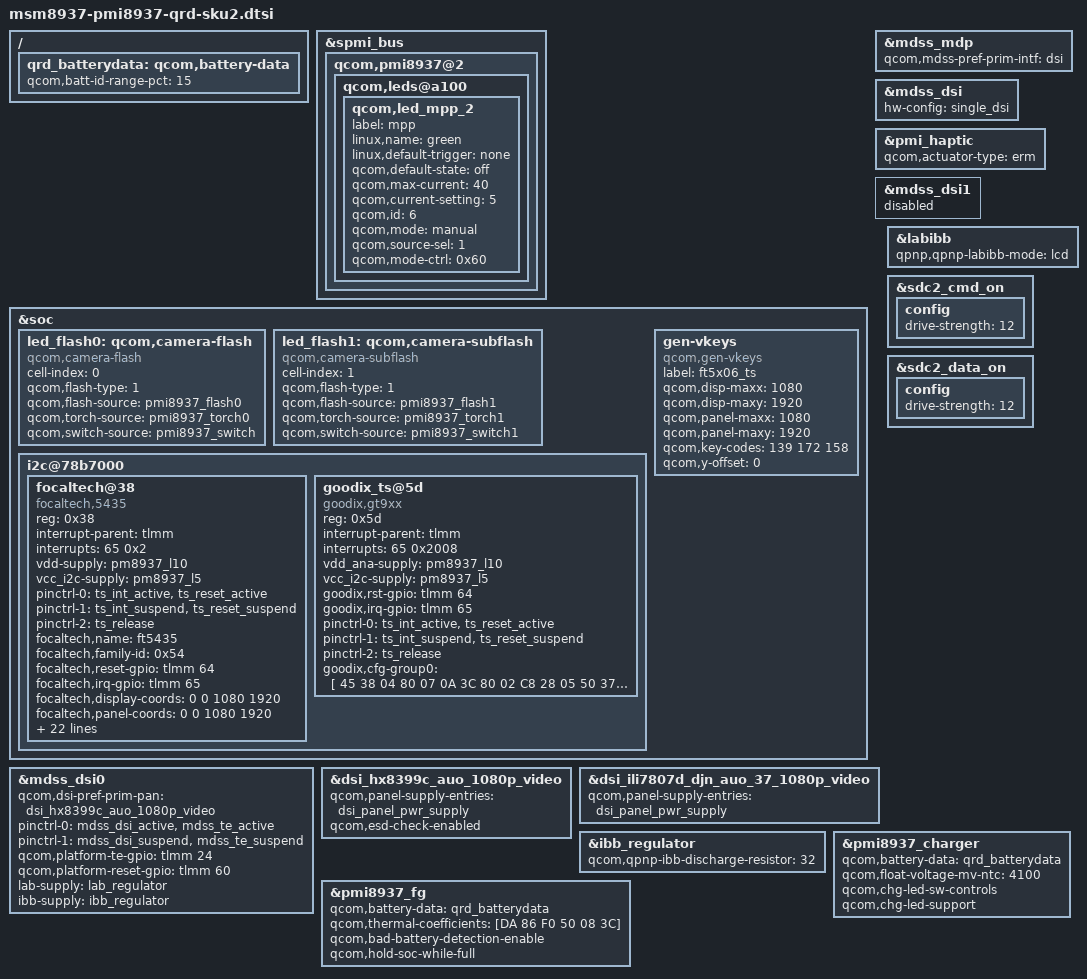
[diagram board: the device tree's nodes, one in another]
/*
 * Copyright (c) 2015-2016, The Linux Foundation. All rights reserved.
 *
 * This program is free software; you can redistribute it and/or modify
 * it under the terms of the GNU General Public License version 2 and
 * only version 2 as published by the Free Software Foundation.
 *
 * This program is distributed in the hope that it will be useful,
 * but WITHOUT ANY WARRANTY; without even the implied warranty of
 * MERCHANTABILITY or FITNESS FOR A PARTICULAR PURPOSE.  See the
 * GNU General Public License for more details.
 */

#include "msm-pmi8937.dtsi"
#include "msm8937-qrd.dtsi"
#include "msm8937-mdss-panels.dtsi"

&spmi_bus {
	qcom,pmi8937@2 {
		qcom,leds@a100 {
			status = "okay";
			qcom,led_mpp_2 {
				label = "mpp";
				linux,name = "green";
				linux,default-trigger = "none";
				qcom,default-state = "off";
				qcom,max-current = <40>;
				qcom,current-setting = <5>;
				qcom,id = <6>;
				qcom,mode = "manual";
				qcom,source-sel = <1>;
				qcom,mode-ctrl = <0x60>;
			};
		};
	};
};

&soc {
	led_flash0: qcom,camera-flash {
		cell-index = <0>;
		compatible = "qcom,camera-flash";
		qcom,flash-type = <1>;
		qcom,flash-source = <&pmi8937_flash0>;
		qcom,torch-source = <&pmi8937_torch0>;
		qcom,switch-source = <&pmi8937_switch>;
	};

	led_flash1: qcom,camera-subflash {
		cell-index = <1>;
		compatible = "qcom,camera-subflash";
		qcom,flash-type = <1>;
		qcom,flash-source = <&pmi8937_flash1>;
		qcom,torch-source = <&pmi8937_torch1>;
		qcom,switch-source = <&pmi8937_switch1>;
	};

	i2c@78b7000 {
		status = "okay";
		focaltech@38 {
                        compatible = "focaltech,5435";
			reg = <0x38>;
			interrupt-parent = <&tlmm>;
                        interrupts = <65 0x2>;
			vdd-supply = <&pm8937_l10>;
			vcc_i2c-supply = <&pm8937_l5>;
			/* pins used by touchscreen */
			pinctrl-names = "pmx_ts_active",
						"pmx_ts_suspend",
						"pmx_ts_release";
			pinctrl-0 = <&ts_int_active &ts_reset_active>;
			pinctrl-1 = <&ts_int_suspend &ts_reset_suspend>;
			pinctrl-2 = <&ts_release>;
                        focaltech,name = "ft5435";
                        focaltech,family-id = <0x54>;
			focaltech,reset-gpio = <&tlmm 64 0x0>;
                        focaltech,irq-gpio = <&tlmm 65 0x2008>;
		        focaltech,display-coords = <0 0 1080 1920>;
		        focaltech,panel-coords = <0 0 1080 1920>;
		        focaltech,button-map= <139 172 158>;
			focaltech,no-force-update;
			focaltech,i2c-pull-up;
			focaltech,group-id = <1>;
                        focaltech,hard-reset-delay-ms = <200>;
			focaltech,soft-reset-delay-ms = <200>;
                        focaltech,num-max-touches = <10>;
                        focaltech,fw-delay-aa-ms = <2>;
                        focaltech,fw-delay-55-ms = <2>;
                        focaltech,fw-upgrade-id1 = <0x54>;
                        focaltech,fw-upgrade-id2 = <0x2c>;
			focaltech,fw-delay-readid-ms = <10>;
			focaltech,fw-delay-era-flsh-ms = <2000>;
                        focaltech,fw-auto-cal;
                        focaltech,fw-vkey-support;
                        focaltech,resume-in-workqueue;
                        focaltech,num-virtual-key = <3>;
                        focal,virtual_key_1 = <172 500 2040>;/*home*/
                        focal,virtual_key_2 = <139 200 2040>;/*menu*/
                        focal,virtual_key_3 = <158 800 2040>;/*back*/
			/* Underlying clocks used by secure touch */
			clock-names = "iface_clk", "core_clk";
			clocks = <&clock_gcc clk_gcc_blsp1_ahb_clk>,
				<&clock_gcc clk_gcc_blsp1_qup3_i2c_apps_clk>;
		};
             goodix_ts@5d {
			compatible = "goodix,gt9xx";
			reg = <0x5d>;
			interrupt-parent = <&tlmm>;
			interrupts = <65 0x2008>;
			vdd_ana-supply = <&pm8937_l10>;
			vcc_i2c-supply = <&pm8937_l5>;
			goodix,rst-gpio = <&tlmm 64 0x00>;
			goodix,irq-gpio = <&tlmm 65 0x00>;
			pinctrl-names = "pmx_ts_active",
						"pmx_ts_suspend",
						"pmx_ts_release";
			pinctrl-0 = <&ts_int_active &ts_reset_active>;
			pinctrl-1 = <&ts_int_suspend &ts_reset_suspend>;
			pinctrl-2 = <&ts_release>;
		        goodix,cfg-group0 = [
                        45 38 04 80 07 0A 3C 80 02 C8 28 
                        05 50 37 03 05 00 00 00 00 11 11 
                        05 16 19 1E 14 87 27 CC 56 58 D3 
                        07 00 00 02 D2 02 11 00 00 00 00 
                        00 03 40 14 14 00 00 3C 64 8F D0 
                        52 08 19 00 04 9F 3F 00 93 46 00 
                        89 4D 00 89 55 00 78 5F 00 78 00 
                        00 00 00 00 00 00 00 00 00 00 00 
                        00 00 00 00 00 00 00 00 00 00 00 
                        00 00 00 00 00 00 00 00 00 00 00 
                        00 00 01 02 03 04 05 06 07 08 0B 
                        0A 09 00 17 16 15 14 13 12 11 10 
                        0F 0E 0D 0C FF FF FF FF FF FF 1E 
                        1F 20 22 24 28 29 0A 08 06 05 04 
                        02 00 FF FF FF 00 00 00 00 00 00 
                        00 00 00 23 32 41 00 00 00 00 00 
                        00 00 00 00 00 5A 00 00 00 00 00 
                        00 00 00 28 5A 00 00 00 00 00 00 
                        00 00 00 00 00 00 00 00 00 00 00 
                        00 00 00 00 00 00 00 00 00 00 00 
                        00 00 00 00 00 00 0C 01];
		};
	};

	gen-vkeys {
		compatible = "qcom,gen-vkeys";
		label = "ft5x06_ts";
		qcom,disp-maxx = <1080>;
		qcom,disp-maxy = <1920>;
		qcom,panel-maxx = <1080>;
		qcom,panel-maxy = <1920>;
		qcom,key-codes = <139 172 158>;
		qcom,y-offset = <0>;
	};
};

&mdss_mdp {
	qcom,mdss-pref-prim-intf = "dsi";
};

&mdss_dsi {
	hw-config = "single_dsi";
};

&mdss_dsi0 {
	qcom,dsi-pref-prim-pan = <&dsi_hx8399c_auo_1080p_video>;
	pinctrl-names = "mdss_default", "mdss_sleep";
	pinctrl-0 = <&mdss_dsi_active &mdss_te_active>;
	pinctrl-1 = <&mdss_dsi_suspend &mdss_te_suspend>;

	qcom,platform-te-gpio = <&tlmm 24 0>;
	qcom,platform-reset-gpio = <&tlmm 60 0>;
};

&pmi_haptic {
	status = "okay";
	qcom,actuator-type = "erm";
	/delete-property/ qcom,lra-auto-res-mode;
	/delete-property/ qcom,lra-high-z;
	/delete-property/ qcom,lra-res-cal-period;
	/delete-property/ qcom,correct-lra-drive-freq;
	/delete-property/ qcom,misc-trim-error-rc19p2-clk-reg-present;
};

&mdss_dsi1 {
	status = "disabled";
};


&dsi_hx8399c_auo_1080p_video {
	
	qcom,panel-supply-entries = <&dsi_panel_pwr_supply>;
};

/*djin 2*/
/*
&dsi_ili7807d_djn_1080p_video {
	qcom,esd-check-enabled;
	qcom,panel-supply-entries = <&dsi_panel_pwr_supply>;
};
*/

&dsi_hx8399c_auo_1080p_video {
	qcom,esd-check-enabled;
	qcom,panel-supply-entries = <&dsi_panel_pwr_supply>;
};

&dsi_ili7807d_djn_auo_37_1080p_video {
	qcom,panel-supply-entries = <&dsi_panel_pwr_supply>;
};

&mdss_dsi0 {
	lab-supply = <&lab_regulator>;
	ibb-supply = <&ibb_regulator>;
};
&labibb {
	status = "ok";
	qpnp,qpnp-labibb-mode = "lcd";
};

&ibb_regulator {
	qcom,qpnp-ibb-discharge-resistor = <32>;
};

&sdc2_cmd_on {
	config {
		drive-strength = <12>;
	};
};

&sdc2_data_on {
	config {
		drive-strength = <12>;
	};
};

/ {
	qrd_batterydata: qcom,battery-data {
		qcom,batt-id-range-pct = <15>;
		#include "batterydata_Amazon_4V4_4000mAh.dtsi"
	};
};

&pmi8937_charger {
	qcom,battery-data = <&qrd_batterydata>;
	qcom,float-voltage-mv-ntc = <4100>;
	qcom,chg-led-sw-controls;
	qcom,chg-led-support;
	status = "okay";
};

&pmi8937_fg {
	qcom,battery-data = <&qrd_batterydata>;
	qcom,thermal-coefficients = [DA 86 F0 50 08 3C];
	qcom,bad-battery-detection-enable;
	qcom,hold-soc-while-full;
};

/*
&flash_led {
	/delete-node/ qcom,flash_1;
	/delete-node/ qcom,torch_1;
};
*/
